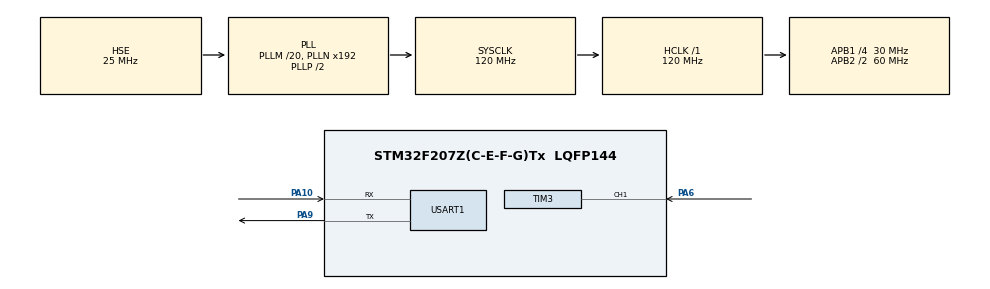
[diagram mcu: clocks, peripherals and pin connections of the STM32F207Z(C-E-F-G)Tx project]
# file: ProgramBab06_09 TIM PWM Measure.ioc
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Mcu.Family=STM32F2
Mcu.Name=STM32F207Z(C-E-F-G)Tx
Mcu.Package=LQFP144
NVIC.PriorityGroup=NVIC_PRIORITYGROUP_4
NVIC.TIM3_IRQn=true\:0\:0\:false\:false\:true\:true\:true
PA10.Mode=Asynchronous
PA10.Signal=USART1_RX
PA6.Signal=S_TIM3_CH1
PA9.Mode=Asynchronous
PA9.Signal=USART1_TX
PH0-OSC_IN.Mode=HSE-External-Oscillator
PH0-OSC_IN.Signal=RCC_OSC_IN
PH1-OSC_OUT.Mode=HSE-External-Oscillator
PH1-OSC_OUT.Signal=RCC_OSC_OUT
ProjectManager.HeapSize=0x200
ProjectManager.StackSize=0x400
ProjectManager.TargetToolchain=STM32CubeIDE
RCC.48MHZClocksFreq_Value=60000000
RCC.AHBFreq_Value=120000000
RCC.APB1CLKDivider=RCC_HCLK_DIV4
RCC.APB1Freq_Value=30000000
RCC.APB1TimFreq_Value=60000000
RCC.APB2CLKDivider=RCC_HCLK_DIV2
RCC.APB2Freq_Value=60000000
RCC.APB2TimFreq_Value=120000000
RCC.CortexFreq_Value=120000000
RCC.HCLKFreq_Value=120000000
RCC.HSE_VALUE=25000000
RCC.HSI_VALUE=16000000
RCC.LSE_VALUE=32768
RCC.PLLM=20
RCC.PLLSourceVirtual=RCC_PLLSOURCE_HSE
RCC.SYSCLKFreq_VALUE=120000000
RCC.SYSCLKSource=RCC_SYSCLKSOURCE_PLLCLK
RCC.VCOOutputFreq_Value=240000000
SH.S_TIM3_CH1.0=TIM3_CH1,Input_Capture1_from_TI1
SH.S_TIM3_CH1.1=TIM3_CH1,Input_Capture2_from_TI1
SH.S_TIM3_CH1.2=TIM3_CH1,TriggerSource_TI1FP1
TIM3.Channel-Input_Capture1_from_TI1=TIM_CHANNEL_1
TIM3.Channel-Input_Capture2_from_TI1=TIM_CHANNEL_2
TIM3.ICPolarity_CH2=TIM_INPUTCHANNELPOLARITY_FALLING
TIM3.Period=0xFFFF
USART1.VirtualMode=VM_ASYNC
VP_TIM3_VS_ClockSourceINT.Mode=Internal
VP_TIM3_VS_ControllerModeReset.Mode=Reset Mode
board=custom

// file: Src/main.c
/* USER CODE BEGIN Header */
/**
  ******************************************************************************
  * @file           : main.c
  * @brief          : Main program body
  ******************************************************************************
  * @attention
  *
  * <h2><center>&copy; Copyright (c) 2019 STMicroelectronics.
  * All rights reserved.</center></h2>
  *
  * This software component is licensed by ST under BSD 3-Clause license,
  * the "License"; You may not use this file except in compliance with the
  * License. You may obtain a copy of the License at:
  *                        opensource.org/licenses/BSD-3-Clause
  *
  ******************************************************************************
  */
/* USER CODE END Header */
#include "main.h"
#include "tim.h"
#include "usart.h"
#include "gpio.h"

/* USER CODE BEGIN Includes */
#include <stdio.h>
/* USER CODE END Includes */

/* USER CODE BEGIN PV */
typedef struct{

  float Frequency;
  float DutyCycle;

}PWMDataTypedef;

/* Captured Value */
__IO uint32_t            uwIC2Value = 0;
/* Duty Cycle Value */
__IO float            uwDutyCycle = 0;
/* Frequency Value */
__IO float            uwFrequency = 0;

PWMDataTypedef PWMData;

/* USER CODE END PV */

void SystemClock_Config(void);

int main(void)
{

  /* MCU Configuration--------------------------------------------------------*/

  /* Reset of all peripherals, Initializes the Flash interface and the Systick. */
  HAL_Init();

  /* Configure the system clock */
  SystemClock_Config();

  /* Initialize all configured peripherals */
  MX_GPIO_Init();
  MX_TIM3_Init();
  MX_USART1_UART_Init();
  /* USER CODE BEGIN 2 */
  printf("PWM Signal Measurement...\r\n");
  if(HAL_TIM_IC_Start_IT(&htim3, TIM_CHANNEL_1) != HAL_OK)
  {
    /* Starting Error */
    Error_Handler();
  }

  if(HAL_TIM_IC_Start_IT(&htim3, TIM_CHANNEL_2) != HAL_OK)
  {
    /* Starting Error */
    Error_Handler();
  }

  /* USER CODE END 2 */

  /* Infinite loop */
  while (1)
  {

    /* USER CODE BEGIN 3 */
   printf("Duty Cycle %.2f %%\r\n",uwDutyCycle);
   printf("Frequency %.2f Hz\r\n",uwFrequency);
   uwDutyCycle=0;
   uwFrequency=0;
   HAL_Delay(1000);

  }
  /* USER CODE END 3 */
}

void SystemClock_Config(void)
{
  RCC_OscInitTypeDef RCC_OscInitStruct = {0};
  RCC_ClkInitTypeDef RCC_ClkInitStruct = {0};

  /** Initializes the RCC Oscillators according to the specified parameters
  * in the RCC_OscInitTypeDef structure.
  */
  RCC_OscInitStruct.OscillatorType = RCC_OSCILLATORTYPE_HSE;
  RCC_OscInitStruct.HSEState = RCC_HSE_ON;
  RCC_OscInitStruct.PLL.PLLState = RCC_PLL_ON;
  RCC_OscInitStruct.PLL.PLLSource = RCC_PLLSOURCE_HSE;
  RCC_OscInitStruct.PLL.PLLM = 20;
  RCC_OscInitStruct.PLL.PLLN = 192;
  RCC_OscInitStruct.PLL.PLLP = RCC_PLLP_DIV2;
  RCC_OscInitStruct.PLL.PLLQ = 4;
  if (HAL_RCC_OscConfig(&RCC_OscInitStruct) != HAL_OK)
  {
    Error_Handler();
  }
  /** Initializes the CPU, AHB and APB buses clocks
  */
  RCC_ClkInitStruct.ClockType = RCC_CLOCKTYPE_HCLK|RCC_CLOCKTYPE_SYSCLK
                              |RCC_CLOCKTYPE_PCLK1|RCC_CLOCKTYPE_PCLK2;
  RCC_ClkInitStruct.SYSCLKSource = RCC_SYSCLKSOURCE_PLLCLK;
  RCC_ClkInitStruct.AHBCLKDivider = RCC_SYSCLK_DIV1;
  RCC_ClkInitStruct.APB1CLKDivider = RCC_HCLK_DIV4;
  RCC_ClkInitStruct.APB2CLKDivider = RCC_HCLK_DIV2;

  if (HAL_RCC_ClockConfig(&RCC_ClkInitStruct, FLASH_LATENCY_3) != HAL_OK)
  {
    Error_Handler();
  }
}

/* USER CODE BEGIN 4 */
void HAL_TIM_IC_CaptureCallback(TIM_HandleTypeDef *htim){

	  if (htim->Channel == HAL_TIM_ACTIVE_CHANNEL_1)
	  {
	    //printf("TIM Callback\r\n");
		  /* Get the Input Capture value */
	    uwIC2Value = HAL_TIM_ReadCapturedValue(htim, TIM_CHANNEL_1);

	    if (uwIC2Value != 0)
	    {
	      /* Duty cycle computation */
	      uwDutyCycle = ((HAL_TIM_ReadCapturedValue(htim, TIM_CHANNEL_2)) * 100) / uwIC2Value;

	      /* uwFrequency computation
	      TIM2 counter clock = (RCC_Clocks.HCLK_Frequency)/2 */
	      uwFrequency = (HAL_RCC_GetHCLKFreq())/2 / uwIC2Value;
	    }
	    else
	    {
	      uwDutyCycle = 0;
	      uwFrequency = 0;
	    }
	  }

}
/* USER CODE END 4 */

void Error_Handler(void)
{
}

/************************ (C) COPYRIGHT STMicroelectronics *****END OF FILE****/
